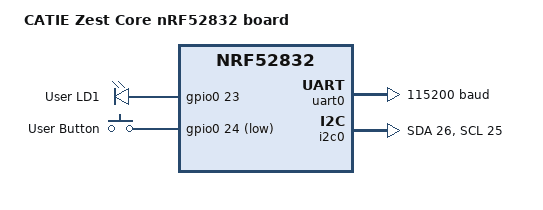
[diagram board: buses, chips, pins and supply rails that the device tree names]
/*
 * Copyright (c) 2020
 *
 * SPDX-License-Identifier: Apache-2.0
 */

/dts-v1/;
#include <nordic/nrf52832_qfaa.dtsi>
#include "zest_core_nrf52832-pinctrl.dtsi"

/ {
	model = "CATIE Zest Core nRF52832 board";
	compatible = "catie,zest-core-nrf52832";

	chosen {
		zephyr,console = &uart0;
		zephyr,shell-uart = &uart0;
		zephyr,uart-mcumgr = &uart0;
		zephyr,bt-mon-uart = &uart0;
		zephyr,bt-c2h-uart = &uart0;
		zephyr,sram = &sram0;
		zephyr,flash = &flash0;
	};

	leds {
		compatible = "gpio-leds";
		led_1: led_1 {
			gpios = <&gpio0 23 GPIO_ACTIVE_HIGH>;
			label = "User LD1";
		};
	};

	gpio_keys {
		compatible = "gpio-keys";
		user_button: button {
			label = "User Button";
			gpios = <&gpio0 24 GPIO_ACTIVE_LOW>;
		};
	};

	aliases {
		led0 = &led_1;
		sw0 = &user_button;
	};
};

&gpio0 {
	status = "okay";
};

&uart0 {
	status = "okay";
	compatible = "nordic,nrf-uarte";
	current-speed = <115200>;
	pinctrl-0 = <&uart0_default>;
	pinctrl-names = "default";
};

&i2c0 {
	compatible = "nordic,nrf-twi";
	status = "okay";
	sda-pin = <26>;
	scl-pin = <25>;
};
